# OCP2SCP2_L4_CFG register map
Vendor: Texas Instruments
Peripheral module from a debugger description file (folder am572x).
Registers are 32-bit, read-only, reset 0x1 unless marked. A register's access mark holds for its fields unless they carry their own. Offsets are as the file gives them; lines under a group give offsets from that group; [hi:lo] are bit positions; {n}, {i} and the like mark numbered series; 'fields as' and 'values as' point back to an identical list; <NAME> marks a mode.

## OCP2SCP2_L4_CFG
0x00 OCP2SCP_REVISION reset not defined — IP Revision Identifier (X.Y.R)
  [31:0] REVISION — IP revision
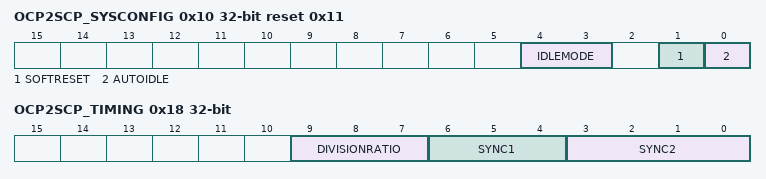
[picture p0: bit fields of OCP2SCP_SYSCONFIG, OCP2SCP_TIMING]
0x10 OCP2SCP_SYSCONFIG access per field reset 0x11 — SYSTEM CONFIGURATION REGISTER
  [4:3] IDLEMODE rw — 00 Force Idle. An idle request is acknowledged unconditionally. 01 No Idle. An idle request is never acknowledged. 10 Smart Idle. The acknowledgement to an idle request is given based on the internal activity (see 4.1.2). 11 Smart Idle Wakeup.
    0=ForceIdle (An idle request is acknowledged unconditionally.); 1=NoIdle (An idle request is never acknowledged.); 2=SmartIdle (The acknowledgement to an idle request is given based on the internal activity (see 4.1.2).)
  [1] SOFTRESET rw — Software Reset. Set this bit to 1 to trigger a module reset. The bit is automatically reset by the hardware. During reads, it always returns 0.
    0=Normal Mode; 1=Reset (The module is reset.)
  [0] AUTOIDLE rw — OCP clock gating control.
    0=FreeRun (Internal Interface OCP clock is free-running); 1=Automatic internal OCP clock gating, based on the OCP interface activity
0x14 OCP2SCP_SYSSTATUS — System Status register.
  [0] RESETDONE
    1=Complete (Reset completed); 0=InProgress (Internal Reset is on-going)
0x18 OCP2SCP_TIMING access per field — Timing constraints for the OCP2SCP module.
  [9:7] DIVISIONRATIO rw — Division Ration of the SCP clock in relation to OCP input clock.
  [6:4] SYNC1 rw — Number of SCPclock cycles defining SYNC1
  [3:0] SYNC2 rw — Number of SCPclock cycles defining SYNC2
